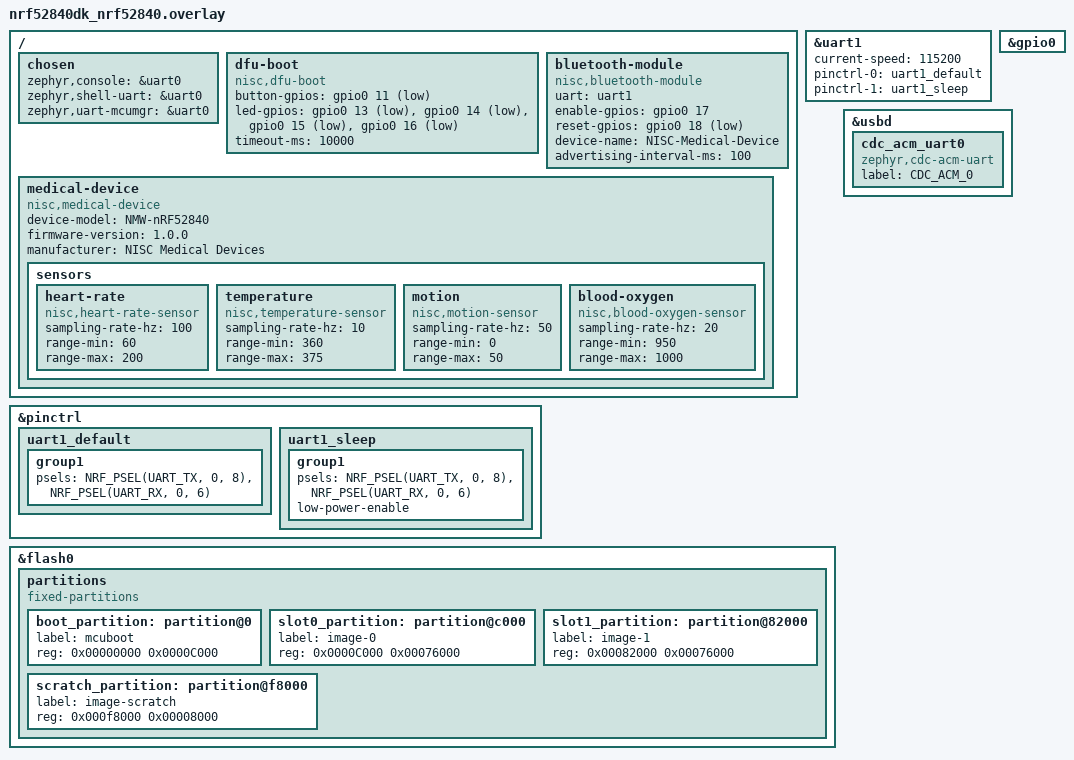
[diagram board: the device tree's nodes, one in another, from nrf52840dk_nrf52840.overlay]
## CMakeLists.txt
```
cmake_minimum_required(VERSION 3.20.0)

# Add custom board root
set(BOARD_ROOT ${CMAKE_CURRENT_SOURCE_DIR})

find_package(Zephyr REQUIRED HINTS $ENV{ZEPHYR_BASE})
project(medical_wearable_app)

target_sources(app PRIVATE 
    src/main.c
    src/system.c
    src/thread_manager.c
    src/safe_queue.c
    src/safe_buffer.c
    src/medical_device.c
    src/diagnostics.c
    src/config.c
    src/hardware.c
)

# Register shell commands only if shell is enabled
zephyr_library_sources_ifdef(CONFIG_SHELL
    src/shell_commands.c
)
```

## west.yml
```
manifest:
  version: "0.13"
  
  defaults:
    remote: zephyrproject
    
  remotes:
    - name: zephyrproject
      url-base: https://github.com/zephyrproject-rtos
      
  projects:
    - name: zephyr
      repo-path: zephyr
      revision: v3.5.0
      import:
        path-prefix: deps
        name-allowlist:
          - cmsis
          - hal_nordic   # Nordic HAL (essential for nRF52840)
          - nrfx         # Nordic drivers (essential)
          - segger
          - tinycrypt    # Required for Bluetooth crypto
  
  self:
    path: app
```

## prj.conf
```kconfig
# Use newlib for proper printf floating point support
CONFIG_NEWLIB_LIBC=y
# CONFIG_NEWLIB_LIBC_FLOAT_PRINTF=y

# Threading and synchronization
CONFIG_MULTITHREADING=y

# Memory management (increased for BLE)
CONFIG_MAIN_STACK_SIZE=4096
CONFIG_SYSTEM_WORKQUEUE_STACK_SIZE=4096

# USB Console Support (USB-C virtual console)
CONFIG_CONSOLE=y
CONFIG_UART_CONSOLE=y
CONFIG_USB_DEVICE_STACK=y
CONFIG_USB_DEVICE_PRODUCT="NISC Medical Wearable"
CONFIG_USB_DEVICE_MANUFACTURER="NISC Medical Devices"
CONFIG_USB_DEVICE_VID=0x2FE3
CONFIG_USB_DEVICE_PID=0x0001
CONFIG_USB_CDC_ACM=y
CONFIG_USB_DEVICE_INITIALIZE_AT_BOOT=y

# Hardware GPIO Support for LEDs
CONFIG_GPIO=y

# Performance monitoring
CONFIG_THREAD_MONITOR=y
CONFIG_THREAD_NAME=y

# Enable logging (using default deferred mode for BLE compatibility)
CONFIG_LOG=y
CONFIG_LOG_DEFAULT_LEVEL=3

# Debug support
CONFIG_DEBUG=y
CONFIG_ASSERT=y
CONFIG_DEBUG_INFO=y

# Hardware abstraction
CONFIG_HWINFO=y

# Shell disabled to prevent interference with BLE and logging
# Re-enable only if you need interactive shell commands
# CONFIG_SHELL=y
# CONFIG_SHELL_BACKEND_SERIAL=y
# CONFIG_KERNEL_SHELL=y
# CONFIG_DEVICE_SHELL=y

# Bluetooth Low Energy support
CONFIG_BT=y
CONFIG_BT_PERIPHERAL=y
CONFIG_BT_DEVICE_NAME="NISC-Medical"
CONFIG_BT_DEVICE_APPEARANCE=833
CONFIG_BT_MAX_CONN=1
CONFIG_BT_MAX_PAIRED=1
CONFIG_TINYCRYPT=y

# Bluetooth advertising
CONFIG_BT_BROADCASTER=y
CONFIG_BT_EXT_ADV=n

# GATT services for connection support
CONFIG_BT_GATT_SERVICE_CHANGED=y

# GAP and GATT features
CONFIG_BT_GAP_PERIPHERAL_PREF_PARAMS=y
CONFIG_BT_PERIPHERAL_PREF_MIN_INT=24
CONFIG_BT_PERIPHERAL_PREF_MAX_INT=40
CONFIG_BT_PERIPHERAL_PREF_LATENCY=0
CONFIG_BT_PERIPHERAL_PREF_TIMEOUT=400
CONFIG_BT_GATT_DYNAMIC_DB=y

# Connection parameters
CONFIG_BT_CONN_PARAM_UPDATE_TIMEOUT=5000
CONFIG_BT_AUTO_PHY_UPDATE=y
CONFIG_BT_AUTO_DATA_LEN_UPDATE=y

# Settings and storage (optional - for bonding)
# CONFIG_BT_SETTINGS=y
# CONFIG_SETTINGS=y
# CONFIG_FLASH=y
# CONFIG_FLASH_MAP=y
# CONFIG_NVS=y

# DFU Boot support (enable MCUboot separately if needed)
# CONFIG_BOOTLOADER_MCUBOOT=y
# CONFIG_MCUBOOT_SERIAL=y
# CONFIG_MCUBOOT_SERIAL_UART=y

# Serial communication for Bluetooth module
CONFIG_SERIAL=y
CONFIG_UART_CONSOLE=y
CONFIG_UART_INTERRUPT_DRIVEN=y

# GPIO interrupt support for button (implied by drivers; no explicit symbol)

# Additional BLE buffers and memory
CONFIG_BT_L2CAP_TX_BUF_COUNT=8
CONFIG_BT_ATT_PREPARE_COUNT=2
CONFIG_BT_BUF_ACL_RX_SIZE=251
CONFIG_BT_BUF_ACL_TX_SIZE=251

# Increase BLE thread stack sizes (prevent stack overflow in BT RX thread)
CONFIG_BT_RX_STACK_SIZE=2048
CONFIG_BT_HCI_TX_STACK_SIZE=1536
CONFIG_SYSTEM_WORKQUEUE_STACK_SIZE=2048

# Increase logging for debugging
# CONFIG_LOG_MODE_IMMEDIATE=y  # Not compatible with BLE software Link Layer
# CONFIG_BT_DEBUG_LOG=y  # Deprecated, use CONFIG_BT_LOG_LEVEL instead
```

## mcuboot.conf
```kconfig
# MCUboot Configuration File
# This file is used when building with MCUboot bootloader support

# MCUboot specific settings
CONFIG_BOOTLOADER_MCUBOOT=y
CONFIG_MCUBOOT_SIGNATURE_KEY_FILE="bootloader/mcuboot-rsa-2048.pem"

# MCUmgr for DFU
CONFIG_MCUMGR=y
CONFIG_MCUMGR_TRANSPORT_UART=y
CONFIG_MCUMGR_TRANSPORT_UART_MTU=256
CONFIG_MCUMGR_CMD_IMG_MGMT=y
CONFIG_MCUMGR_CMD_OS_MGMT=y
CONFIG_MCUMGR_CMD_STAT_MGMT=y
CONFIG_MCUMGR_CMD_FS_MGMT=n

# Image management
CONFIG_IMG_MANAGER=y
CONFIG_IMG_ENABLE_IMAGE_CHECK=y
CONFIG_FLASH=y
CONFIG_FLASH_PAGE_LAYOUT=y
CONFIG_FLASH_MAP=y
CONFIG_STREAM_FLASH=y

# Increase buffer sizes for DFU
CONFIG_SYSTEM_WORKQUEUE_STACK_SIZE=2304
CONFIG_MAIN_STACK_SIZE=4096
CONFIG_MBEDTLS_CFG_FILE="mcuboot-mbedtls-cfg.h"

# Enable reboot command
CONFIG_REBOOT=y

# Stats for monitoring
CONFIG_STATS=y
CONFIG_STATS_NAMES=y
```

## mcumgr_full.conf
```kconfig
# MCUmgr Full Configuration
# Use this file to enable complete MCUmgr functionality
# Build with: west build -- -DEXTRA_CONF_FILE=mcumgr_full.conf

#==============================================================================
# MCUmgr Core Configuration
#==============================================================================

# Enable MCUmgr subsystem
CONFIG_MCUMGR=y

# SMP (Simple Management Protocol) - The protocol MCUmgr uses
CONFIG_BASE64=y
CONFIG_CRC=y
CONFIG_CBOR=y

#==============================================================================
# Transport Configuration - UART over USB
#==============================================================================

CONFIG_MCUMGR_TRANSPORT_UART=y
CONFIG_MCUMGR_TRANSPORT_UART_MTU=256

# For faster uploads, try:
# CONFIG_MCUMGR_TRANSPORT_UART_MTU=512

# SMP over UART
CONFIG_MCUMGR_SMP_UART=y
CONFIG_UART_ASYNC_API=y

#==============================================================================
# MCUmgr Command Groups
#==============================================================================

# Image Management - Upload/test/confirm firmware
CONFIG_MCUMGR_GRP_IMG=y
CONFIG_MCUMGR_GRP_IMG_UPLOAD_CHECK_HOOK=y
CONFIG_MCUMGR_GRP_IMG_STATUS_HOOKS=y

# OS Management - Reset, echo, datetime, taskstat
CONFIG_MCUMGR_GRP_OS=y
CONFIG_MCUMGR_GRP_OS_RESET_HOOK=y
CONFIG_MCUMGR_GRP_OS_TASKSTAT=y
CONFIG_MCUMGR_GRP_OS_ECHO=y
CONFIG_MCUMGR_GRP_OS_INFO=y

# Statistics Management - Get device stats
CONFIG_MCUMGR_GRP_STAT=y
CONFIG_STATS=y
CONFIG_STATS_NAMES=y

# Shell Management - Execute shell commands remotely
CONFIG_MCUMGR_GRP_SHELL=y

# File System Management (optional)
# CONFIG_MCUMGR_GRP_FS=y
# CONFIG_FILE_SYSTEM=y
# CONFIG_FILE_SYSTEM_LITTLEFS=y

# Logging Management (optional)
# CONFIG_MCUMGR_GRP_LOG=y

#==============================================================================
# Image Manager - Flash and Image Handling
#==============================================================================

CONFIG_IMG_MANAGER=y
CONFIG_IMG_ENABLE_IMAGE_CHECK=y
CONFIG_FLASH=y
CONFIG_FLASH_PAGE_LAYOUT=y
CONFIG_FLASH_MAP=y
CONFIG_STREAM_FLASH=y

# Storage partition for images
CONFIG_BOOTLOADER_MCUBOOT=y

#==============================================================================
# MCUboot Configuration
#==============================================================================

# Signing key (CHANGE THIS PATH if needed)
CONFIG_MCUBOOT_SIGNATURE_KEY_FILE="bootloader/mcuboot-rsa-2048.pem"

# Image version (can be overridden at build time)
CONFIG_MCUBOOT_IMGTOOL_SIGN_VERSION="1.0.0"

# Boot algorithm
CONFIG_BOOT_SWAP_USING_MOVE=y

# Security features
# CONFIG_MCUBOOT_DOWNGRADE_PREVENTION=y  # Uncomment for production
# CONFIG_MCUBOOT_HW_DOWNGRADE_PREVENTION=y

# Validate image before booting
CONFIG_MCUBOOT_VALIDATE_PRIMARY_SLOT=y

#==============================================================================
# Memory Configuration - Increased for MCUmgr
#==============================================================================

# Stack sizes for MCUmgr operations
CONFIG_SYSTEM_WORKQUEUE_STACK_SIZE=2304
CONFIG_MAIN_STACK_SIZE=4096

# Heap (if using malloc)
# CONFIG_HEAP_MEM_POOL_SIZE=4096

#==============================================================================
# Logging Configuration
#==============================================================================

CONFIG_LOG=y
CONFIG_LOG_DEFAULT_LEVEL=3  # 3=INFO, 4=DEBUG
CONFIG_MCUBOOT_LOG_LEVEL_INF=y

# Log backends
CONFIG_LOG_BACKEND_UART=y
CONFIG_LOG_BACKEND_SHOW_COLOR=n  # Disable colors for cleaner MCUmgr output

#==============================================================================
# System Features
#==============================================================================

# Reboot support (required for MCUmgr reset)
CONFIG_REBOOT=y

# Thread monitoring (for taskstat command)
CONFIG_THREAD_MONITOR=y
CONFIG_THREAD_NAME=y
CONFIG_THREAD_RUNTIME_STATS=y

#==============================================================================
# Optional: Bluetooth Transport (for wireless DFU)
#==============================================================================

# Uncomment to enable BLE DFU:
# CONFIG_MCUMGR_TRANSPORT_BT=y
# CONFIG_MCUMGR_SMP_BT=y
# CONFIG_MCUMGR_SMP_BT_AUTHEN=n  # Set to 'y' for pairing requirement

#==============================================================================
# Debugging and Development
#==============================================================================

# Enable for debugging MCUmgr issues
# CONFIG_MCUMGR_LOG_LEVEL_DBG=y
# CONFIG_LOG_DEFAULT_LEVEL=4

# Assertions for safety
CONFIG_ASSERT=y
CONFIG_ASSERT_LEVEL=2

#==============================================================================
# End of Configuration
#==============================================================================

# Build with this config:
#   west build -b nrf52840dk_nrf52840 -- -DEXTRA_CONF_FILE=mcumgr_full.conf
#
# Then flash:
#   west flash
#
# Test MCUmgr:
#   mcumgr --conntype serial --connstring dev=/dev/ttyACM0 echo hello
```

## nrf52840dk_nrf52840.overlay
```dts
/*
 * Device Tree Overlay for nRF52840DK DFU and Bluetooth Configuration
 * 
 * This overlay configures:
 * - DFU boot process with button support
 * - Bluetooth Low Energy advertising
 * - Serial communication for Bluetooth module
 * - GPIO interrupts for button detection
 */

/ {
    chosen {
        zephyr,console = &uart0;
        zephyr,shell-uart = &uart0;
        zephyr,uart-mcumgr = &uart0;
    };

    /* DFU Boot Configuration */
    dfu-boot {
        compatible = "nisc,dfu-boot";
        button-gpios = <&gpio0 11 GPIO_ACTIVE_LOW>;
        led-gpios = <&gpio0 13 GPIO_ACTIVE_LOW>,  /* LED1 - Status */
                   <&gpio0 14 GPIO_ACTIVE_LOW>,  /* LED2 - Heartbeat */
                   <&gpio0 15 GPIO_ACTIVE_LOW>,  /* LED3 - Communication */
                   <&gpio0 16 GPIO_ACTIVE_LOW>;  /* LED4 - Error */
        timeout-ms = <10000>;
    };

    /* Bluetooth Module Configuration */
    bluetooth-module {
        compatible = "nisc,bluetooth-module";
        uart = <&uart1>;
        enable-gpios = <&gpio0 17 GPIO_ACTIVE_HIGH>;
        reset-gpios = <&gpio0 18 GPIO_ACTIVE_LOW>;
        device-name = "NISC-Medical-Device";
        advertising-interval-ms = <100>;
    };

    /* Medical Device Configuration */
    medical-device {
        compatible = "nisc,medical-device";
        device-model = "NMW-nRF52840";
        firmware-version = "1.0.0";
        manufacturer = "NISC Medical Devices";
        
        sensors {
            heart-rate {
                compatible = "nisc,heart-rate-sensor";
                sampling-rate-hz = <100>;
                range-min = <60>;
                range-max = <200>;
            };
            
            temperature {
                compatible = "nisc,temperature-sensor";
                sampling-rate-hz = <10>;
                range-min = <360>;  /* 36.0°C * 10 */
                range-max = <375>;  /* 37.5°C * 10 */
            };
            
            motion {
                compatible = "nisc,motion-sensor";
                sampling-rate-hz = <50>;
                range-min = <0>;
                range-max = <50>;   /* 5.0g * 10 */
            };
            
            blood-oxygen {
                compatible = "nisc,blood-oxygen-sensor";
                sampling-rate-hz = <20>;
                range-min = <950>;  /* 95.0% * 10 */
                range-max = <1000>; /* 100.0% * 10 */
            };
        };
    };
};

/* UART1 Configuration for Bluetooth Module */
&uart1 {
    status = "okay";
    current-speed = <115200>;
    pinctrl-names = "default", "sleep";
    pinctrl-0 = <&uart1_default>;
    pinctrl-1 = <&uart1_sleep>;
};

/* GPIO Configuration */
&gpio0 {
    status = "okay";
};

/* Pin Control Configuration */
&pinctrl {
    uart1_default: uart1_default {
        group1 {
            psels = <NRF_PSEL(UART_TX, 0, 8)>,
                    <NRF_PSEL(UART_RX, 0, 6)>;
        };
    };
    
    uart1_sleep: uart1_sleep {
        group1 {
            psels = <NRF_PSEL(UART_TX, 0, 8)>,
                    <NRF_PSEL(UART_RX, 0, 6)>;
            low-power-enable;
        };
    };
};


/* Flash Configuration for DFU */
&flash0 {
    partitions {
        compatible = "fixed-partitions";
        #address-cells = <1>;
        #size-cells = <1>;

        boot_partition: partition@0 {
            label = "mcuboot";
            reg = <0x00000000 0x0000C000>;
        };
        
        slot0_partition: partition@c000 {
            label = "image-0";
            reg = <0x0000C000 0x00076000>;
        };
        
        slot1_partition: partition@82000 {
            label = "image-1";
            reg = <0x00082000 0x00076000>;
        };
        
        scratch_partition: partition@f8000 {
            label = "image-scratch";
            reg = <0x000f8000 0x00008000>;
        };
    };
};

/* USB Configuration */
&usbd {
    status = "okay";
    cdc_acm_uart0: cdc_acm_uart0 {
        compatible = "zephyr,cdc-acm-uart";
        label = "CDC_ACM_0";
    };
};
```

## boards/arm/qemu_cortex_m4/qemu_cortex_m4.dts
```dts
/* SPDX-License-Identifier: Apache-2.0 */

/dts-v1/;

#include <ti/lm3s6965.dtsi>

/ {
	model = "QEMU Cortex-M4";
	compatible = "ti,lm3s6965evb-qemu", "ti,lm3s6965";

	/* Override CPU to be Cortex-M4 */
	cpus {
		/delete-node/ cpu@0;
		
		cpu@0 {
			device_type = "cpu";
			compatible = "arm,cortex-m4";
			reg = <0>;
		};
	};

	/* Override memory sizes for our 256KB/1024KB configuration */
	sram0: memory@20000000 {
		compatible = "mmio-sram";
		reg = <0x20000000 (256*1024)>;  /* 256KB RAM */
	};

	aliases {
		uart-0 = &uart0;
	};

	chosen {
		zephyr,sram = &sram0;
		zephyr,flash = &flash0;
		zephyr,console = &uart0;
		zephyr,shell-uart = &uart0;
		zephyr,uart-pipe = &uart0;
	};
};

/* Override flash size */
&flash0 {
	reg = <0x00000000 (1024*1024)>;  /* 1024KB Flash */
};

&uart0 {
	status = "okay";
	current-speed = <115200>;
};

/* Keep uart1 and uart2 but disabled - this prevents driver compilation errors 
   while maintaining the DTSi structure */
&uart1 {
	status = "disabled";
	current-speed = <115200>;  /* Required by driver even when disabled */
};

&uart2 {
	status = "disabled";
	current-speed = <115200>;  /* Required by driver even when disabled */
};

&gpio0 {
	status = "okay";
};

&gpio1 {
	status = "okay";
};

&gpio2 {
	status = "okay";
};
```

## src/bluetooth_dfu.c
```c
/**
 * @file bluetooth_dfu.c
 * @brief Bluetooth Low Energy DFU service implementation
 * @details Implements BLE advertising and DFU service for firmware updates
 * 
 * @author NISC Medical Devices
 * @version 1.0.0
 * @date 2024
 */

#include <zephyr/kernel.h>
#include <zephyr/bluetooth/bluetooth.h>
#include <zephyr/bluetooth/gatt.h>
#include <zephyr/bluetooth/uuid.h>
#include <zephyr/bluetooth/conn.h>
#include <zephyr/sys/printk.h>
#include <zephyr/sys/crc.h>
#include <zephyr/storage/flash_map.h>

#include "bluetooth_dfu.h"
#include "bootloader.h"

/*============================================================================*/
/* DFU Service UUIDs                                                          */
/*============================================================================*/

static struct bt_uuid_128 dfu_service_uuid = BT_UUID_INIT_128(
    0x30, 0x15, 0x00, 0x00, 0x00, 0x00, 0x00, 0x00,
    0x00, 0x00, 0x00, 0x00, 0x00, 0x00, 0x00, 0x00
);

static struct bt_uuid_128 dfu_char_uuid = BT_UUID_INIT_128(
    0x31, 0x15, 0x00, 0x00, 0x00, 0x00, 0x00, 0x00,
    0x00, 0x00, 0x00, 0x00, 0x00, 0x00, 0x00, 0x00
);

static struct bt_uuid_128 dfu_notify_uuid = BT_UUID_INIT_128(
    0x32, 0x15, 0x00, 0x00, 0x00, 0x00, 0x00, 0x00,
    0x00, 0x00, 0x00, 0x00, 0x00, 0x00, 0x00, 0x00
);

/*============================================================================*/
/* Global Variables                                                           */
/*============================================================================*/

static dfu_context_t dfu_ctx = {
    .state = DFU_STATE_IDLE,
    .total_size = 0,
    .received_size = 0,
    .crc32 = 0,
    .connected = false,
    .conn = NULL
};

static struct bt_gatt_service dfu_service;
static struct bt_gatt_attr dfu_attrs[3];
static struct bt_gatt_ccc_cfg dfu_ccc_cfg[BT_GATT_CCC_MAX] = {};

/*============================================================================*/
/* DFU Characteristic Callbacks                                               */
/*============================================================================*/

static ssize_t dfu_char_write(struct bt_conn *conn, const struct bt_gatt_attr *attr,
                              const void *buf, uint16_t len, uint16_t offset, uint8_t flags)
{
    ARG_UNUSED(conn);
    ARG_UNUSED(attr);
    ARG_UNUSED(offset);
    ARG_UNUSED(flags);
    
    if (len < 3) {
        printk("DFU: Invalid packet length: %u\n", len);
        bluetooth_dfu_send_status(DFU_STATUS_INVALID_DATA);
        return -EINVAL;
    }
    
    dfu_packet_t packet;
    packet.command = ((uint8_t*)buf)[0];
    packet.length = ((uint16_t*)buf)[1];
    
    if (packet.length > DFU_MAX_PACKET_SIZE) {
        printk("DFU: Packet too large: %u\n", packet.length);
        bluetooth_dfu_send_status(DFU_STATUS_INVALID_DATA);
        return -EINVAL;
    }
    
    if (len < (3 + packet.length)) {
        printk("DFU: Incomplete packet\n");
        bluetooth_dfu_send_status(DFU_STATUS_INVALID_DATA);
        return -EINVAL;
    }
    
    memcpy(packet.data, &((uint8_t*)buf)[3], packet.length);
    
    return bluetooth_dfu_process_packet(&packet);
}

static void dfu_ccc_cfg_changed(const struct bt_gatt_attr *attr, uint16_t value)
{
    ARG_UNUSED(attr);
    
    bool notif_enabled = (value == BT_GATT_CCC_NOTIFY);
    
    printk("DFU notifications %s\n", notif_enabled ? "enabled" : "disabled");
}

/*============================================================================*/
/* GATT Service Definition                                                    */
/*============================================================================*/

BT_GATT_SERVICE_DEFINE(dfu_svc,
    BT_GATT_PRIMARY_SERVICE(&dfu_service_uuid),
    BT_GATT_CHARACTERISTIC(&dfu_char_uuid.uuid,
                          BT_GATT_CHRC_WRITE | BT_GATT_CHRC_WRITE_WITHOUT_RESP,
                          BT_GATT_PERM_WRITE,
                          NULL, dfu_char_write, NULL),
    BT_GATT_CHARACTERISTIC(&dfu_notify_uuid.uuid,
                          BT_GATT_CHRC_NOTIFY,
                          BT_GATT_PERM_NONE,
                          NULL, NULL, NULL),
    BT_GATT_CCC(dfu_ccc_cfg, dfu_ccc_cfg_changed),
);

/*============================================================================*/
/* Connection Callbacks                                                       */
/*============================================================================*/

static void connected(struct bt_conn *conn, uint8_t err)
{
    if (err) {
        printk("DFU: Connection failed (err %u)\n", err);
        return;
    }
    
    dfu_ctx.connected = true;
    dfu_ctx.conn = conn;
    
    printk("DFU: Client connected\n");
    bluetooth_dfu_send_status(DFU_STATUS_OK);
}

static void disconnected(struct bt_conn *conn, uint8_t reason)
{
    ARG_UNUSED(conn);
    
    dfu_ctx.connected = false;
    dfu_ctx.conn = NULL;
    dfu_ctx.state = DFU_STATE_IDLE;
    
    printk("DFU: Client disconnected (reason %u)\n", reason);
}

static struct bt_conn_cb conn_callbacks = {
    .connected = connected,
    .disconnected = disconnected,
};

/*============================================================================*/
/* DFU Processing Functions                                                   */
/*============================================================================*/

static int dfu_start_update(const dfu_packet_t *packet)
{
    if (packet->length < 8) {
        printk("DFU: Start command too short\n");
        return -EINVAL;
    }
    
    dfu_ctx.total_size = *(uint32_t*)&packet->data[0];
    dfu_ctx.crc32 = *(uint32_t*)&packet->data[4];
    dfu_ctx.received_size = 0;
    dfu_ctx.state = DFU_STATE_RECEIVING;
    
    printk("DFU: Starting update - Size: %u bytes, CRC32: 0x%08x\n", 
           dfu_ctx.total_size, dfu_ctx.crc32);
    
    return 0;
}

static int dfu_process_data(const dfu_packet_t *packet)
{
    if (dfu_ctx.state != DFU_STATE_RECEIVING) {
        printk("DFU: Not in receiving state\n");
        return -EINVAL;
    }
    
    if ((dfu_ctx.received_size + packet->length) > dfu_ctx.total_size) {
        printk("DFU: Data exceeds total size\n");
        return -EINVAL;
    }
    
    /* TODO: Write data to flash */
    printk("DFU: Received %u bytes (total: %u/%u)\n", 
           packet->length, dfu_ctx.received_size + packet->length, dfu_ctx.total_size);
    
    dfu_ctx.received_size += packet->length;
    
    if (dfu_ctx.received_size >= dfu_ctx.total_size) {
        dfu_ctx.state = DFU_STATE_VALIDATING;
        printk("DFU: All data received, validating...\n");
        
        /* TODO: Validate CRC32 */
        dfu_ctx.state = DFU_STATE_COMPLETE;
        bluetooth_dfu_send_status(DFU_STATUS_OK);
    }
    
    return 0;
}

static int dfu_end_update(const dfu_packet_t *packet)
{
    ARG_UNUSED(packet);
    
    if (dfu_ctx.state != DFU_STATE_RECEIVING) {
        printk("DFU: Not in receiving state\n");
        return -EINVAL;
    }
    
    if (dfu_ctx.received_size != dfu_ctx.total_size) {
        printk("DFU: Incomplete data received\n");
        return -EINVAL;
    }
    
    dfu_ctx.state = DFU_STATE_VALIDATING;
    printk("DFU: Update complete, validating...\n");
    
    /* TODO: Validate and install firmware */
    dfu_ctx.state = DFU_STATE_COMPLETE;
    bluetooth_dfu_send_status(DFU_STATUS_OK);
    
    return 0;
}

static int dfu_abort_update(const dfu_packet_t *packet)
{
    ARG_UNUSED(packet);
    
    printk("DFU: Update aborted\n");
    dfu_ctx.state = DFU_STATE_IDLE;
    dfu_ctx.received_size = 0;
    dfu_ctx.total_size = 0;
    
    bluetooth_dfu_send_status(DFU_STATUS_OK);
    return 0;
}

/*============================================================================*/
/* Public API Implementation                                                  */
/*============================================================================*/

int bluetooth_dfu_init(void)
{
    int ret;
    
    printk("Initializing Bluetooth DFU service...\n");
    
    /* Register connection callbacks */
    bt_conn_cb_register(&conn_callbacks);
    
    /* Initialize DFU context */
    dfu_ctx.state = DFU_STATE_IDLE;
    dfu_ctx.connected = false;
    dfu_ctx.conn = NULL;
    
    printk("Bluetooth DFU service initialized\n");
    return 0;
}

int bluetooth_dfu_start_advertising(void)
{
    struct bt_le_adv_param adv_param = {
        .id = BT_ID_DEFAULT,
        .options = BT_LE_ADV_OPT_CONNECTABLE | BT_LE_ADV_OPT_USE_NAME,
        .interval_min = BT_GAP_ADV_FAST_INT_MIN_2,
        .interval_max = BT_GAP_ADV_FAST_INT_MAX_2,
    };
    
    const char *adv_name = "NISC-DFU";
    int ret;
    
    ret = bt_le_adv_start(&adv_param, NULL, 0, NULL, 0);
    if (ret) {
        printk("Error: DFU advertising failed to start (ret: %d)\n", ret);
        return ret;
    }
    
    printk("DFU advertising started: %s\n", adv_name);
    return 0;
}

int bluetooth_dfu_stop_advertising(void)
{
    int ret = bt_le_adv_stop();
    if (ret) {
        printk("Error: Failed to stop DFU advertising (ret: %d)\n", ret);
        return ret;
    }
    
    printk("DFU advertising stopped\n");
    return 0;
}

int bluetooth_dfu_get_context(dfu_context_t *ctx)
{
    if (!ctx) {
        return -EINVAL;
    }
    
    *ctx = dfu_ctx;
    return 0;
}

int bluetooth_dfu_process_packet(const dfu_packet_t *packet)
{
    if (!packet) {
        return -EINVAL;
    }
    
    switch (packet->command) {
        case DFU_CMD_START:
            return dfu_start_update(packet);
            
        case DFU_CMD_DATA:
            return dfu_process_data(packet);
            
        case DFU_CMD_END:
            return dfu_end_update(packet);
            
        case DFU_CMD_ABORT:
            return dfu_abort_update(packet);
            
        case DFU_CMD_STATUS:
            bluetooth_dfu_send_status(DFU_STATUS_OK);
            return 0;
            
        default:
            printk("DFU: Unknown command: 0x%02x\n", packet->command);
            bluetooth_dfu_send_status(DFU_STATUS_ERROR);
            return -EINVAL;
    }
}

int bluetooth_dfu_send_status(uint8_t status)
{
    if (!dfu_ctx.connected || !dfu_ctx.conn) {
        return -ENOTCONN;
    }
    
    int ret = bt_gatt_notify(dfu_ctx.conn, &dfu_svc.attrs[2], &status, sizeof(status));
    if (ret) {
        printk("Error: Failed to send DFU status notification (ret: %d)\n", ret);
        return ret;
    }
    
    printk("DFU status sent: 0x%02x\n", status);
    return 0;
}
```

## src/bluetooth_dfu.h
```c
/**
 * @file bluetooth_dfu.h
 * @brief Bluetooth Low Energy DFU service for NISC Medical Wearable Device
 * @details Provides BLE advertising and DFU service for firmware updates
 * 
 * @author NISC Medical Devices
 * @version 1.0.0
 * @date 2024
 */

#ifndef BLUETOOTH_DFU_H
#define BLUETOOTH_DFU_H

#include <zephyr/kernel.h>
#include <zephyr/bluetooth/bluetooth.h>
#include <zephyr/bluetooth/gatt.h>
#include <zephyr/bluetooth/uuid.h>
#include <stdint.h>
#include <stdbool.h>

/*============================================================================*/
/* DFU Service Configuration                                                  */
/*============================================================================*/

/** @brief DFU Service UUID */
#define DFU_SERVICE_UUID             0x00001530
#define DFU_CHAR_UUID                0x00001531
#define DFU_CHAR_NOTIFY_UUID         0x00001532

/** @brief DFU Commands */
#define DFU_CMD_START                0x01
#define DFU_CMD_DATA                 0x02
#define DFU_CMD_END                  0x03
#define DFU_CMD_ABORT                0x04
#define DFU_CMD_STATUS               0x05

/** @brief DFU Status Codes */
#define DFU_STATUS_OK                0x00
#define DFU_STATUS_ERROR             0x01
#define DFU_STATUS_BUSY              0x02
#define DFU_STATUS_INVALID_DATA      0x03

/** @brief Maximum DFU data packet size */
#define DFU_MAX_PACKET_SIZE          244

/*============================================================================*/
/* DFU State Machine                                                          */
/*============================================================================*/

typedef enum {
    DFU_STATE_IDLE = 0,
    DFU_STATE_RECEIVING,
    DFU_STATE_VALIDATING,
    DFU_STATE_WRITING,
    DFU_STATE_COMPLETE,
    DFU_STATE_ERROR
} dfu_state_t;

/*============================================================================*/
/* DFU Data Structures                                                        */
/*============================================================================*/

typedef struct {
    uint8_t command;
    uint16_t length;
    uint8_t data[DFU_MAX_PACKET_SIZE];
} dfu_packet_t;

typedef struct {
    dfu_state_t state;
    uint32_t total_size;
    uint32_t received_size;
    uint32_t crc32;
    bool connected;
    struct bt_conn *conn;
} dfu_context_t;

/*============================================================================*/
/* Public API Functions                                                       */
/*============================================================================*/

/**
 * @brief Initialize Bluetooth DFU service
 * @return 0 on success, negative error code otherwise
 */
int bluetooth_dfu_init(void);

/**
 * @brief Start DFU advertising
 * @return 0 on success, negative error code otherwise
 */
int bluetooth_dfu_start_advertising(void);

/**
 * @brief Stop DFU advertising
 * @return 0 on success, negative error code otherwise
 */
int bluetooth_dfu_stop_advertising(void);

/**
 * @brief Get DFU context
 * @param ctx Pointer to dfu_context_t structure
 * @return 0 on success
 */
int bluetooth_dfu_get_context(dfu_context_t *ctx);

/**
 * @brief Process DFU packet
 * @param packet Pointer to dfu_packet_t
 * @return 0 on success, negative error code otherwise
 */
int bluetooth_dfu_process_packet(const dfu_packet_t *packet);

/**
 * @brief Send DFU status notification
 * @param status Status code to send
 * @return 0 on success, negative error code otherwise
 */
int bluetooth_dfu_send_status(uint8_t status);

#endif /* BLUETOOTH_DFU_H */
```

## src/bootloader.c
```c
/**
 * @file bootloader.c
 * @brief Secure bootloader implementation for NISC Medical Wearable Device
 * @details Implements DFU support, image validation, and secure boot for medical device firmware updates.
 * 
 * @author NISC Medical Devices
 * @version 1.0.0
 * @date 2024
 */

#include <zephyr/kernel.h>
#include <zephyr/device.h>
#include <zephyr/drivers/gpio.h>
#include <zephyr/sys/printk.h>
#include <zephyr/storage/flash_map.h>
#include <zephyr/dfu/mcuboot.h>
#include <zephyr/bluetooth/bluetooth.h>
#include <zephyr/bluetooth/gatt.h>
#include <zephyr/bluetooth/services/nus.h>
#include <zephyr/usb/usb_device.h>
#include <zephyr/usb/usbd.h>
#include <zephyr/drivers/uart.h>
#include <zephyr/sys/crc.h>

#include "bootloader.h"
#include "common.h"

/*============================================================================*/
/* Bootloader Configuration                                                   */
/*============================================================================*/

/** @brief Magic number for image validation */
#define IMAGE_MAGIC_NUMBER           0x4E495343  /* "NISC" */

/** @brief Button GPIO configuration */
#define BOOTLOADER_BUTTON_PORT       "GPIO_0"
#define BOOTLOADER_BUTTON_PIN        11
#define BOOTLOADER_BUTTON_FLAGS      (GPIO_PULL_UP | GPIO_INT_EDGE_FALLING)

/** @brief LED GPIO configuration for bootloader status */
#define BOOTLOADER_STATUS_LED_PORT   "GPIO_0"
#define BOOTLOADER_STATUS_LED_PIN    13

/** @brief DFU Service UUID */
#define DFU_SERVICE_UUID             0x00001530
#define DFU_CHAR_UUID                0x00001531

/** @brief Bootloader state */
typedef enum {
    BOOTLOADER_STATE_INIT,
    BOOTLOADER_STATE_WAITING,
    BOOTLOADER_STATE_DFU_MODE,
    BOOTLOADER_STATE_BOOTING_APP
} bootloader_state_t;

/*============================================================================*/
/* Global Variables                                                           */
/*============================================================================*/

static const struct device *button_dev;
static const struct device *led_dev;
static struct gpio_callback button_callback;
static boot_info_t boot_info;
static bootloader_state_t current_state = BOOTLOADER_STATE_INIT;
static bool button_pressed = false;
static uint32_t button_press_start = 0;

/* Bluetooth DFU Service */
static struct bt_uuid_128 dfu_service_uuid = BT_UUID_INIT_128(
    0x30, 0x15, 0x00, 0x00, 0x00, 0x00, 0x00, 0x00,
    0x00, 0x00, 0x00, 0x00, 0x00, 0x00, 0x00, 0x00
);

static struct bt_uuid_128 dfu_char_uuid = BT_UUID_INIT_128(
    0x31, 0x15, 0x00, 0x00, 0x00, 0x00, 0x00, 0x00,
    0x00, 0x00, 0x00, 0x00, 0x00, 0x00, 0x00, 0x00
);

/*============================================================================*/
/* Private Function Declarations                                              */
/*============================================================================*/

static void button_pressed_callback(const struct device *dev, struct gpio_callback *cb, uint32_t pins);
static void bootloader_blink_led(uint32_t count, uint32_t delay_ms);
static int bootloader_init_hardware(void);
static int bootloader_init_bluetooth(void);
static void bootloader_advertise_dfu(void);
static boot_status_t bootloader_validate_app_image(void);
static void bootloader_show_status(boot_status_t status);

/*============================================================================*/
/* Button Interrupt Handler                                                   */
/*============================================================================*/

static void button_pressed_callback(const struct device *dev, struct gpio_callback *cb, uint32_t pins)
{
    ARG_UNUSED(dev);
    ARG_UNUSED(cb);
    ARG_UNUSED(pins);
    
    if (!button_pressed) {
        button_pressed = true;
        button_press_start = k_uptime_get_32();
        printk("Button pressed - starting timer\n");
    }
}

/*============================================================================*/
/* Hardware Initialization                                                    */
/*============================================================================*/

static int bootloader_init_hardware(void)
{
    int ret;
    
    /* Initialize button GPIO */
    button_dev = device_get_binding(BOOTLOADER_BUTTON_PORT);
    if (!button_dev) {
        printk("Error: Button device not found\n");
        return -ENODEV;
    }
    
    ret = gpio_pin_configure(button_dev, BOOTLOADER_BUTTON_PIN, 
                            GPIO_INPUT | BOOTLOADER_BUTTON_FLAGS);
    if (ret) {
        printk("Error: Failed to configure button GPIO (ret: %d)\n", ret);
        return ret;
    }
    
    /* Setup button interrupt */
    gpio_init_callback(&button_callback, button_pressed_callback, 
                      BIT(BOOTLOADER_BUTTON_PIN));
    ret = gpio_add_callback(button_dev, &button_callback);
    if (ret) {
        printk("Error: Failed to add button callback (ret: %d)\n", ret);
        return ret;
    }
    
    ret = gpio_pin_interrupt_configure(button_dev, BOOTLOADER_BUTTON_PIN, 
                                      GPIO_INT_EDGE_FALLING);
    if (ret) {
        printk("Error: Failed to configure button interrupt (ret: %d)\n", ret);
        return ret;
    }
    
    /* Initialize status LED */
    led_dev = device_get_binding(BOOTLOADER_STATUS_LED_PORT);
    if (!led_dev) {
        printk("Error: LED device not found\n");
        return -ENODEV;
    }
    
    ret = gpio_pin_configure(led_dev, BOOTLOADER_STATUS_LED_PIN, GPIO_OUTPUT);
    if (ret) {
        printk("Error: Failed to configure LED GPIO (ret: %d)\n", ret);
        return ret;
    }
    
    /* Turn off LED initially */
    gpio_pin_set(led_dev, BOOTLOADER_STATUS_LED_PIN, 0);
    
    return 0;
}

/*============================================================================*/
/* LED Status Indication                                                      */
/*============================================================================*/

static void bootloader_blink_led(uint32_t count, uint32_t delay_ms)
{
    for (uint32_t i = 0; i < count; i++) {
        gpio_pin_set(led_dev, BOOTLOADER_STATUS_LED_PIN, 1);
        k_sleep(K_MSEC(delay_ms));
        gpio_pin_set(led_dev, BOOTLOADER_STATUS_LED_PIN, 0);
        k_sleep(K_MSEC(delay_ms));
    }
}

static void bootloader_show_status(boot_status_t status)
{
    switch (status) {
        case BOOT_STATUS_OK:
            /* Single long blink - success */
            bootloader_blink_led(1, 500);
            break;
        case BOOT_STATUS_ERROR_VALIDATION:
            /* Two short blinks - validation error */
            bootloader_blink_led(2, 200);
            break;
        case BOOT_STATUS_ERROR_SIGNATURE:
            /* Three short blinks - signature error */
            bootloader_blink_led(3, 200);
            break;
        case BOOT_STATUS_ERROR_VERSION:
            /* Four short blinks - version error */
            bootloader_blink_led(4, 200);
            break;
        case BOOT_STATUS_ERROR_CORRUPTION:
            /* Five short blinks - corruption error */
            bootloader_blink_led(5, 200);
            break;
        default:
            /* Continuous blinking - unknown error */
            for (int i = 0; i < 10; i++) {
                bootloader_blink_led(1, 100);
            }
            break;
    }
}

/*============================================================================*/
/* Bluetooth DFU Service                                                      */
/*============================================================================*/

static int bootloader_init_bluetooth(void)
{
    int ret;
    
    ret = bt_enable(NULL);
    if (ret) {
        printk("Error: Bluetooth init failed (ret: %d)\n", ret);
        return ret;
    }
    
    printk("Bluetooth initialized for DFU mode\n");
    return 0;
}

static void bootloader_advertise_dfu(void)
{
    struct bt_le_adv_param adv_param = {
        .id = BT_ID_DEFAULT,
        .options = BT_LE_ADV_OPT_CONNECTABLE | BT_LE_ADV_OPT_USE_NAME,
        .interval_min = BT_GAP_ADV_FAST_INT_MIN_2,
        .interval_max = BT_GAP_ADV_FAST_INT_MAX_2,
    };
    
    const char *adv_name = "NISC-DFU";
    int ret;
    
    ret = bt_le_adv_start(&adv_param, NULL, 0, NULL, 0);
    if (ret) {
        printk("Error: Advertising failed to start (ret: %d)\n", ret);
        return;
    }
    
    printk("DFU advertising started: %s\n", adv_name);
    
    /* Blink LED to indicate DFU mode */
    while (current_state == BOOTLOADER_STATE_DFU_MODE) {
        bootloader_blink_led(1, 1000);
        k_sleep(K_MSEC(1000));
    }
}

/*============================================================================*/
/* Image Validation                                                           */
/*============================================================================*/

static boot_status_t bootloader_validate_app_image(void)
{
    const struct flash_area *fa;
    image_header_t header;
    int ret;
    
    /* Get flash area for application */
    ret = flash_area_open(FLASH_AREA_ID(image_0), &fa);
    if (ret) {
        printk("Error: Failed to open flash area (ret: %d)\n", ret);
        return BOOT_STATUS_ERROR_CORRUPTION;
    }
    
    /* Read image header */
    ret = flash_area_read(fa, 0, &header, sizeof(header));
    if (ret) {
        printk("Error: Failed to read image header (ret: %d)\n", ret);
        flash_area_close(fa);
        return BOOT_STATUS_ERROR_CORRUPTION;
    }
    
    /* Validate magic number */
    if (header.magic != IMAGE_MAGIC_NUMBER) {
        printk("Error: Invalid magic number: 0x%08x\n", header.magic);
        flash_area_close(fa);
        return BOOT_STATUS_ERROR_VALIDATION;
    }
    
    /* Validate image size */
    if (header.image_size > BOOTLOADER_MAX_IMAGE_SIZE) {
        printk("Error: Image size too large: %u bytes\n", header.image_size);
        flash_area_close(fa);
        return BOOT_STATUS_ERROR_VALIDATION;
    }
    
    /* Calculate and verify CRC32 */
    uint8_t *image_data = k_malloc(header.image_size);
    if (!image_data) {
        printk("Error: Failed to allocate memory for image validation\n");
        flash_area_close(fa);
        return BOOT_STATUS_ERROR_CORRUPTION;
    }
    
    ret = flash_area_read(fa, sizeof(header), image_data, header.image_size);
    if (ret) {
        printk("Error: Failed to read image data (ret: %d)\n", ret);
        k_free(image_data);
        flash_area_close(fa);
        return BOOT_STATUS_ERROR_CORRUPTION;
    }
    
    uint32_t calculated_crc = crc32_ieee(image_data, header.image_size, 0);
    if (calculated_crc != header.crc32) {
        printk("Error: CRC32 mismatch: calculated=0x%08x, stored=0x%08x\n", 
               calculated_crc, header.crc32);
        k_free(image_data);
        flash_area_close(fa);
        return BOOT_STATUS_ERROR_CORRUPTION;
    }
    
    k_free(image_data);
    flash_area_close(fa);
    
    printk("Image validation successful:\n");
    printk("  Version: %u.%u.%u\n", header.version_major, 
           header.version_minor, header.version_patch);
    printk("  Size: %u bytes\n", header.image_size);
    printk("  CRC32: 0x%08x\n", header.crc32);
    
    return BOOT_STATUS_OK;
}

/*============================================================================*/
/* Public API Implementation                                                  */
/*============================================================================*/

int bootloader_init(void)
{
    int ret;
    
    printk("\n=== NISC Medical Device Bootloader ===\n");
    printk("Version: %u.%u.%u\n", BOOTLOADER_VERSION_MAJOR, 
           BOOTLOADER_VERSION_MINOR, BOOTLOADER_VERSION_PATCH);
    
    /* Initialize hardware */
    ret = bootloader_init_hardware();
    if (ret) {
        printk("Error: Hardware initialization failed\n");
        return ret;
    }
    
    /* Initialize boot info */
    boot_info.mode = BOOT_MODE_NORMAL;
    boot_info.boot_count = 0;
    boot_info.last_boot_time = k_uptime_get_32();
    boot_info.reset_reason = 0; /* TODO: Get from hardware */
    boot_info.dfu_requested = false;
    boot_info.button_pressed = false;
    
    current_state = BOOTLOADER_STATE_WAITING;
    
    printk("Bootloader initialized successfully\n");
    return 0;
}

boot_mode_t bootloader_check_boot_mode(void)
{
    boot_mode_t mode = BOOT_MODE_NORMAL;
    
    printk("Checking boot mode...\n");
    
    /* Check for DFU request flag in persistent storage */
    if (boot_info.dfu_requested) {
        printk("DFU mode requested via persistent flag\n");
        mode = BOOT_MODE_DFU;
        boot_info.dfu_requested = false;
    }
    
    /* Check for button press */
    if (button_pressed) {
        uint32_t press_duration = k_uptime_get_32() - button_press_start;
        printk("Button pressed for %u ms\n", press_duration);
        
        if (press_duration >= BOOTLOADER_BUTTON_HOLD_MS) {
            printk("Button held long enough - entering DFU mode\n");
            mode = BOOT_MODE_DFU;
        } else {
            printk("Button held too short - normal boot\n");
        }
        
        button_pressed = false;
    }
    
    boot_info.mode = mode;
    boot_info.button_pressed = button_pressed;
    
    return mode;
}

bool bootloader_wait_for_button(uint32_t timeout_ms)
{
    uint32_t start_time = k_uptime_get_32();
    uint32_t elapsed_time = 0;
    
    printk("Waiting for button press (timeout: %u ms)...\n", timeout_ms);
    
    /* Blink LED to indicate waiting */
    while (elapsed_time < timeout_ms) {
        if (button_pressed) {
            uint32_t press_duration = k_uptime_get_32() - button_press_start;
            printk("Button pressed after %u ms\n", elapsed_time);
            
            if (press_duration >= BOOTLOADER_BUTTON_HOLD_MS) {
                printk("Button held long enough for DFU mode\n");
                return true;
            }
        }
        
        /* Blink LED every 500ms */
        if ((elapsed_time % 500) == 0) {
            gpio_pin_set(led_dev, BOOTLOADER_STATUS_LED_PIN, 1);
            k_sleep(K_MSEC(50));
            gpio_pin_set(led_dev, BOOTLOADER_STATUS_LED_PIN, 0);
        }
        
        k_sleep(K_MSEC(50));
        elapsed_time = k_uptime_get_32() - start_time;
    }
    
    printk("Button wait timeout - proceeding with normal boot\n");
    return false;
}

boot_status_t bootloader_validate_image(const image_header_t *header)
{
    if (!header) {
        return BOOT_STATUS_ERROR_VALIDATION;
    }
    
    /* Validate magic number */
    if (header->magic != IMAGE_MAGIC_NUMBER) {
        return BOOT_STATUS_ERROR_VALIDATION;
    }
    
    /* Validate version */
    if (header->version_major == 0 && header->version_minor == 0) {
        return BOOT_STATUS_ERROR_VERSION;
    }
    
    /* Validate size */
    if (header->image_size == 0 || header->image_size > BOOTLOADER_MAX_IMAGE_SIZE) {
        return BOOT_STATUS_ERROR_VALIDATION;
    }
    
    return BOOT_STATUS_OK;
}

int bootloader_enter_dfu_mode(void)
{
    int ret;
    
    printk("Entering DFU mode...\n");
    current_state = BOOTLOADER_STATE_DFU_MODE;
    
    /* Initialize Bluetooth for DFU */
    ret = bootloader_init_bluetooth();
    if (ret) {
        printk("Error: Failed to initialize Bluetooth for DFU\n");
        return ret;
    }
    
    /* Start advertising */
    bootloader_advertise_dfu();
    
    printk("DFU mode active - waiting for connection\n");
    return 0;
}

int bootloader_start_application(void)
{
    boot_status_t status;
    
    printk("Starting application...\n");
    current_state = BOOTLOADER_STATE_BOOTING_APP;
    
    /* Validate application image */
    status = bootloader_validate_app_image();
    bootloader_show_status(status);
    
    if (status != BOOT_STATUS_OK) {
        printk("Error: Application validation failed\n");
        return -EINVAL;
    }
    
    /* TODO: Jump to application */
    printk("Application validated - would jump to app here\n");
    printk("For now, continuing with normal operation...\n");
    
    return 0;
}

int bootloader_get_info(boot_info_t *info)
{
    if (!info) {
        return -EINVAL;
    }
    
    *info = boot_info;
    return 0;
}

void bootloader_request_dfu(void)
{
    boot_info.dfu_requested = true;
    printk("DFU mode requested for next boot\n");
}

void bootloader_clear_dfu_request(void)
{
    boot_info.dfu_requested = false;
    printk("DFU request flag cleared\n");
}
```

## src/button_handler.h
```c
/**
 * @file button_handler.h
 * @brief Button handling for NISC Medical Wearable Device
 * @details Provides button press detection and debouncing for boot mode selection
 * 
 * @author NISC Medical Devices
 * @version 1.0.0
 * @date 2024
 */

#ifndef BUTTON_HANDLER_H
#define BUTTON_HANDLER_H

#include <zephyr/kernel.h>
#include <zephyr/device.h>
#include <zephyr/drivers/gpio.h>
#include <stdint.h>
#include <stdbool.h>

/*============================================================================*/
/* Button Configuration                                                       */
/*============================================================================*/

/** @brief Button debounce time in milliseconds */
#define BUTTON_DEBOUNCE_MS           50U

/** @brief Button hold time for DFU mode in milliseconds */
#define BUTTON_HOLD_DFU_MS           3000U

/** @brief Button hold time for factory reset in milliseconds */
#define BUTTON_HOLD_RESET_MS         10000U

/** @brief Button GPIO configuration */
#define BUTTON_PORT                  "GPIO_0"
#define BUTTON_PIN                   11
#define BUTTON_FLAGS                 (GPIO_PULL_UP | GPIO_INT_EDGE_FALLING)

/*============================================================================*/
/* Button Events                                                              */
/*============================================================================*/

typedef enum {
    BUTTON_EVENT_NONE = 0,
    BUTTON_EVENT_PRESSED,
    BUTTON_EVENT_RELEASED,
    BUTTON_EVENT_SHORT_PRESS,
    BUTTON_EVENT_LONG_PRESS,
    BUTTON_EVENT_DFU_HOLD,
    BUTTON_EVENT_RESET_HOLD
} button_event_t;

/*============================================================================*/
/* Button State                                                               */
/*============================================================================*/

typedef struct {
    bool pressed;
    bool last_state;
    uint32_t press_start_time;
    uint32_t last_event_time;
    button_event_t last_event;
    uint32_t press_count;
    uint32_t hold_count;
} button_state_t;

/*============================================================================*/
/* Public API Functions                                                       */
/*============================================================================*/

/**
 * @brief Initialize button handler
 * @return 0 on success, negative error code otherwise
 */
int button_handler_init(void);

/**
 * @brief Check for button events
 * @return Button event that occurred
 */
button_event_t button_handler_check_event(void);

/**
 * @brief Wait for button press with timeout
 * @param timeout_ms Timeout in milliseconds
 * @return true if button was pressed
 */
bool button_handler_wait_for_press(uint32_t timeout_ms);

/**
 * @brief Get button state
 * @param state Pointer to button_state_t structure
 * @return 0 on success
 */
int button_handler_get_state(button_state_t *state);

/**
 * @brief Reset button state
 * @return 0 on success
 */
int button_handler_reset_state(void);

/**
 * @brief Enable/disable button interrupts
 * @param enable true to enable, false to disable
 * @return 0 on success
 */
int button_handler_set_interrupts(bool enable);

#endif /* BUTTON_HANDLER_H */
```
